# PWMSS_EPWM register map
Vendor: Texas Instruments
Peripheral module from a debugger description file (folder am437x).
Registers are 16-bit, access per field, no defined reset value unless marked. A register's access mark holds for its fields unless they carry their own. Offsets are as the file gives them; lines under a group give offsets from that group; [hi:lo] are bit positions; {n}, {i} and the like mark numbered series; 'fields as' and 'values as' point back to an identical list; <NAME> marks a mode.

## PWMSS_EPWM
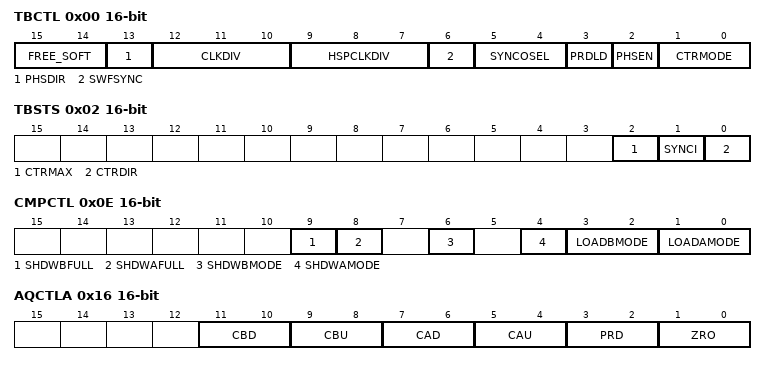
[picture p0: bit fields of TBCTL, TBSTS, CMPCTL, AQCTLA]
0x00 TBCTL rw
  [15:14] FREE_SOFT — Emulation Mode Bits. These bits select the behavior of the ePWM time-base counter during emulation suspend events. Emulation debug events can be set up in the Debug Subsystem.
    3=en_4_0x3 (Free run); 2=en_3_0x2 (Free run); 1=en_2_0x1 (Stop when counter completes a whole cycle. (a) Up-count mode - stop when the time-base counter = period (TBCNT = TBPRD). (b) Down-count mode - stop when the time-base counter = 0000 (TBCNT = 0000h). (c) Up-down-count mode - stop when the time-base counter = 0000 (TBCNT = 0000h).); 0=en_1_0x0 (Stop after the next time-base counter increment or decrement)
  [13] PHSDIR — Phase Direction Bit. This bit is only used when the time-base counter is configured in the up-down-count mode. The PHSDIR bit indicates the direction the time-base counter (TBCNT) will count after a synchronization event occurs and a new phase value is loaded from the phase (TBPHS) register. This is irrespective of the direction of the counter before the synchronization event.. In the up-count and down-count modes this bit is ignored.
    1=en_2_0x1 (Count up after the synchronization event.); 0=en_1_0x0 (Count down after the synchronization event.)
  [12:10] CLKDIV — Time-base Clock Prescale Bits. These bits determine part of the time-base clock prescale value. TBCLK = SYSCLKOUT/(HSPCLKDIV * CLKDIV)
    7=en_8_0x7 (/128); 6=en_7_0x6 (/64); 5=en_6_0x5 (/32); 4=en_5_0x4 (/16); 3=en_4_0x3 (/8); 2=en_3_0x2 (/4); 1=en_2_0x1 (/2); 0=en_1_0x0 (/1 (default on reset))
  [9:7] HSPCLKDIV — High-Speed Time-base Clock Prescale Bits. These bits determine part of the time-base clock prescale value. TBCLK = SYSCLKOUT/(HSPCLKDIV * CLKDIV). This divisor emulates the HSPCLK in the TMS320x281x system as used on the Event Manager (EV) peripheral.
    7=en_8_0x7 (/14); 6=en_7_0x6 (/12); 5=en_6_0x5 (/10); 4=en_5_0x4 (/8); 3=en_4_0x3 (/6); 2=en_3_0x2 (/4); 1=en_2_0x1 (/2 (default on reset)); 0=en_1_0x0 (/1)
  [6] SWFSYNC — Software Forced Synchronization Pulse.
    1=en_2_0x1 (Writing a 1 forces a one-time synchronization pulse to be generated. This event is ORed with the EPWMxSYNCI input of the ePWM module. SWFSYNC is valid (operates) only when EPWMxSYNCI is selected by SYNCOSEL = 00.); 0=en_1_0x0 (Writing a 0 has no effect and reads always return a 0.)
  [5:4] SYNCOSEL — Synchronization Output Select. These bits select the source of the EPWMxSYNCO signal.
    3=en_4_0x3 (Disable EPWMxSYNCO signal); 2=en_3_0x2 (CTR = CMPB - Time-base counter equal to counter-compare B (TBCNT = CMPB)); 1=en_2_0x1 (CTR = 0 - Time-base counter equal to zero (TBCNT = 0000h)); 0=en_1_0x0 (EPWMxSYNC:)
  [3] PRDLD — Active Period Register Load From Shadow Register Select
    1=en_2_0x1 (Load the TBPRD register immediately without using a shadow register. A write or read to the TBPRD register directly accesses the active register.); 0=en_1_0x0 (The period register (TBPRD) is loaded from its shadow register when the time-base counter, TBCNT, is equal to zero. A write or read to the TBPRD register accesses the shadow register.)
  [2] PHSEN — Counter Register Load From Phase Register Enable
    1=en_2_0x1 (Load the time-base counter with the phase register when an EPWMxSYNCI input signal occurs or when a software synchronization is forced by the SWFSYNC bit.); 0=en_1_0x0 (Do not load the time-base counter (TBCNT) from the time-base phase register (TBPHS))
  [1:0] CTRMODE — Counter Mode. The time-base counter mode is normally configured once and not changed during normal operation. If you change the mode of the counter, the change will take effect at the next TBCLK edge and the current counter value shall increment or decrement from the value before the mode change. These bits set the time-base counter mode of operation as follows:
    3=en_4_0x3 (Stop-freeze counter operation (default on reset)); 2=en_3_0x2 (Up-down-count mode); 1=en_2_0x1 (Down-count mode); 0=en_1_0x0 (Up-count mode)
0x02 TBSTS access not given
  [2] CTRMAX — Time-Base Counter Max Latched Status Bit.
    1=en_2_0x1 (Reading a 1 on this bit indicates that the time-base counter reached the max value 0xFFFF. Writing a 1 to this bit will clear the latched event.); 0=en_1_0x0 (Reading a 0 indicates the time-base counter never reached its maximum value. Writing a 0 will have no effect.)
  [1] SYNCI wo — Input Synchronization Latched Status Bit.
    1=en_2_0x1 (Reading a 1 on this bit indicates that an external synchronization event has occurred (EPWMxSYNCI). Writing a 1 to this bit will clear the latched event.); 0=en_1_0x0 (Writing a 0 will have no effect. Reading a 0 indicates no external synchronization event has occurred.)
  [0] CTRDIR ro — Time-Base Counter Direction Status Bit. At reset, the counter is frozen, therefore, this bit has no meaning. To make this bit meaningful, you must first set the appropriate mode via TBCTL[CTRMODE].
    1=en_2_0x1 (Time-Base Counter is currently counting up.); 0=en_1_0x0 (Time-Base Counter is currently counting down.)
0x04 TBPHSHR
  [15:8] TBPHSH rw — Time-base phase high-resolution bits
0x06 TBPHS rw — This register is only available on ePWM instances that include the high-resolution PWM (HRPWM) extension, otherwise, this location is reserved.
  [15:0] TBPHS — These bits set time-base counter phase of the selected ePWM relative to the time-base that is supplying the synchronization input signal. (a) If TBCTL[PHSEN] = 0, then the synchronization event is ignored and the time-base counter is not loaded with the phase. (b) If TBCTL[PHSEN] = 1, then the time-base counter (TBCNT) will be loaded with the phase (TBPHS) when a synchronization event occurs. The synchronization event can be initiated by the input synchronization signal (EPWMxSYNCI) or by a software forced synchronization.
0x08 TBCNT rw
  [15:0] TBCNT — Reading these bits gives the current time-base counter value. Writing to these bits sets the current time-base counter value. The update happens as soon as the write occurs. The write is NOT synchronized to the time-base clock (TBCLK) and the register is not shadowed.
0x0A TBPRD rw
  [15:0] TBPRD — These bits determine the period of the time-base counter. This sets the PWM frequency. Shadowing of this register is enabled and disabled by the TBCTL[PRDLD] bit. By default this register is shadowed. (a) If TBCTL[PRDLD] = 0, then the shadow is enabled and any write or read will automatically go to the shadow register. In this case, the active register will be loaded from the shadow register when the time-base counter equals zero. (b) If TBCTL[PRDLD] = 1, then the shadow is disabled and any write or read will go directly to the active register, that is the register actively controlling the hardware. (c) The active and shadow registers share the same memory map address.
0x0E CMPCTL
  [9] SHDWBFULL ro — Counter-compare B (CMPB) Shadow Register Full Status Flag. This bit self clears once a load-strobe occurs.
    1=en_2_0x1 (Indicates the CMPB shadow FIFO is full. A CPU write will overwrite current shadow value.); 0=en_1_0x0 (CMPB shadow FIFO not full yet)
  [8] SHDWAFULL ro — Counter-compare A (CMPA) Shadow Register Full Status Flag. The flag bit is set when a 32 bit write to CMPA:CMPAHR register or a 16 bit write to CMPA register is made. A 16 bit write to CMPAHR register will not affect the flag. This bit self clears once a load-strobe occurs.
    1=en_2_0x1 (Indicates the CMPA shadow FIFO is full, a CPU write will overwrite the current shadow value.); 0=en_1_0x0 (CMPA shadow FIFO not full yet)
  [6] SHDWBMODE rw — Counter-compare B (CMPB) Register Operating Mode.
    1=en_2_0x1 (Immediate mode. Only the active compare B register is used. All writes and reads directly access the active register for immediate compare action.); 0=en_1_0x0 (Shadow mode. Operates as a double buffer. All writes via the CPU access the shadow register.)
  [4] SHDWAMODE rw — Counter-compare A (CMPA) Register Operating Mode.
    1=en_2_0x1 (Immediate mode. Only the active compare register is used. All writes and reads directly access the active register for immediate compare action); 0=en_1_0x0 (Shadow mode. Operates as a double buffer. All writes via the CPU access the shadow register.)
  [3:2] LOADBMODE rw — Active Counter-Compare B (CMPB) Load From Shadow Select Mode. This bit has no effect in immediate mode (CMPCTL[SHDWBMODE] = 1).
    3=en_4_0x3 (Freeze (no loads possible)); 2=en_3_0x2 (Load on either CTR = 0 or CTR = PRD); 1=en_2_0x1 (Load on CTR = PRD - Time-base counter equal to period (TBCNT = TBPRD)); 0=en_1_0x0 (Load on CTR = 0 - Time-base counter equal to zero (TBCNT = 0000h))
  [1:0] LOADAMODE rw — Active Counter-Compare A (CMPA) Load From Shadow Select Mode. This bit has no effect in immediate mode (CMPCTL[SHDWAMODE] = 1).
    values as LOADBMODE
0x10 CMPAHR — This register is only available on ePWM instances that include the high-resolution PWM (HRPWM) extension; otherwise, this location is reserved.
  [15:8] CMPAHR rw — Compare A High-Resolution register bits for MEP step control. A minimum value of 1h is needed to enable HRPWM capabilities. Valid MEP range of operation 1-255h.
0x12 CMPA rw
  [15:0] CMPA — The value in the active CMPA register is continuously compared to the time-base counter (TBCNT). When the values are equal, the counter-compare module generates a "time-base counter equal to counter compare A" event. This event is sent to the action-qualifier where it is qualified and converted it into one or more actions. These actions can be applied to either the EPWMxA or the EPWMxB output depending on the configuration of the AQCTLA and AQCTLB registers. The actions that can be defined in the AQCTLA and AQCTLB registers include the following. (a) Do nothing the event is ignored. (b) Clear - Pull the EPWMxA and/or EPWMxB signal low. (c) Set - Pull the EPWMxA and/or EPWMxB signal high. (d) Toggle the EPWMxA and/or EPWMxB signal. Shadowing of this register is enabled and disabled by the CMPCTL[SHDWAMODE] bit. By default this register is shadowed. (a) If CMPCTL[SHDWAMODE] = 0, then the shadow is enabled and any write or read will automatically go to the shadow register. In this case, the CMPCTL[LOADAMODE] bit field determines which event will load the active register from the shadow register. (b) Before a write, the CMPCTL[SHDWAFULL] bit can be read to determine if the shadow register is currently full. (c) If CMPCTL[SHDWAMODE] = 1, then the shadow register is disabled and any write or read will go directly to the active register, that is the register actively controlling the hardware. (d) In either mode, the active and shadow registers share the same memory map address.
0x14 CMPB rw
  [15:0] CMPB — The value in the active CMPB register is continuously compared to the time-base counter (TBCNT). When the values are equal, the counter-compare module generates a "time-base counter equal to counter compare B" event. This event is sent to the action-qualifier where it is qualified and converted it into one or more actions. These actions can be applied to either the EPWMxA or the EPWMxB output depending on the configuration of the AQCTLA and AQCTLB registers. The actions that can be defined in the AQCTLA and AQCTLB registers include the following. (a) Do nothing, the event is ignored. (b) Clear - Pull the EPWMxA and/or EPWMxB signal low. (c) Set - Pull the EPWMxA and/or EPWMxB signal high. (d) Toggle the EPWMxA and/or EPWMxB signal. Shadowing of this register is enabled and disabled by the CMPCTL[SHDWBMODE] bit. By default this register is shadowed. (a) If CMPCTL[SHDWBMODE] = 0, then the shadow is enabled and any write or read will automatically go to the shadow register. In this case, the CMPCTL[LOADBMODE] bit field determines which event will load the active register from the shadow register: (b) Before a write, the CMPCTL[SHDWBFULL] bit can be read to determine if the shadow register is currently full. (c) If CMPCTL[SHDWBMODE] = 1, then the shadow register is disabled and any write or read will go directly to the active register, that is the register actively controlling the hardware. (d) In either mode, the active and shadow registers share the same memory map address.
0x16 AQCTLA
  [all] fields
    3=en_4_0x3 (Toggle EPWMxA output - low output signal will be forced high, and a high signal will be forced low.); 2=en_3_0x2 (Set - force EPWMxA output high.); 1=en_2_0x1 (Clear - force EPWMxA output low.); 0=en_1_0x0 (Do nothing (action disabled))
  [11:10] CBD rw — Action when the time-base counter equals the active CMPB register and the counter is decrementing.
  [9:8] CBU rw — Action when the counter equals the active CMPB register and the counter is incrementing.
  [7:6] CAD rw — Action when the counter equals the active CMPA register and the counter is decrementing.
  [5:4] CAU rw — Action when the counter equals the active CMPA register and the counter is incrementing.
  [3:2] PRD rw — Action when the counter equals the period. Note: By definition, in count up-down mode when the counter equals period the direction is defined as 0 or counting down.
  [1:0] ZRO rw — Action when counter equals zero. Note: By definition, in count up-down mode when the counter equals 0 the direction is defined as 1 or counting up.
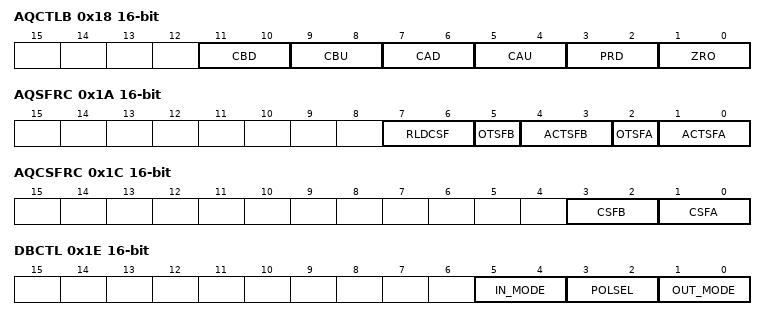
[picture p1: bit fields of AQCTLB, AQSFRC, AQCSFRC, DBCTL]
0x18 AQCTLB
  [all] fields
    3=en_4_0x3 (Toggle EPWMxB output - low output signal will be forced high, and a high signal will be forced low.); 2=en_3_0x2 (Set - force EPWMxB output high.); 1=en_2_0x1 (Clear - force EPWMxB output low.); 0=en_1_0x0 (Do nothing (action disabled))
  [11:10] CBD rw — Action when the counter equals the active CMPB register and the counter is decrementing.
  [9:8] CBU rw — Action when the counter equals the active CMPB register and the counter is incrementing.
  [7:6] CAD rw — Action when the counter equals the active CMPA register and the counter is decrementing.
  [5:4] CAU rw — Action when the counter equals the active CMPA register and the counter is incrementing.
  [3:2] PRD rw — Action when the counter equals the period. Note: By definition, in count up-down mode when the counter equals period the direction is defined as 0 or counting down.
  [1:0] ZRO rw — Action when counter equals zero. Note: By definition, in count up-down mode when the counter equals 0 the direction is defined as 1 or counting up.
0x1A AQSFRC
  [7:6] RLDCSF rw — AQCSFRC Active Register Reload From Shadow Options.
    3=en_4_0x3 (Load immediately (the active register is directly accessed by the CPU and is not loaded from the shadow register).); 2=en_3_0x2 (Load on event counter equals zero or counter equals period); 1=en_2_0x1 (Load on event counter equals period); 0=en_1_0x0 (Load on event counter equals zero)
  [5] OTSFB rw — One-Time Software Forced Event on Output B.
    1=en_2_0x1 (Initiates a single s/w forced event); 0=en_1_0x0 (Writing a 0 (zero) has no effect. Always reads back a 0. This bit is auto cleared once a write to this register is complete, that is, a forced event is initiated. This is a one-shot forced event. It can be overridden by another subsequent event on output B.)
  [4:3] ACTSFB rw — Action when One-Time Software Force B Is invoked
    3=en_4_0x3 (Toggle (Low -> High, High -> Low). Note: This action is not qualified by counter direction (CNT_dir)); 2=en_3_0x2 (Set (high)); 1=en_2_0x1 (Clear (low)); 0=en_1_0x0 (Does nothing (action disabled))
  [2] OTSFA rw — One-Time Software Forced Event on Output A.
    1=en_2_0x1 (Initiates a single software forced event.); 0=en_1_0x0 (Writing a 0 (zero) has no effect. Always reads back a 0. This bit is auto cleared once a write to this register is complete (that is, a forced event is initiated).)
  [1:0] ACTSFA rw — Action When One-Time Software Force A Is Invoked.
    3=en_4_0x3 (Toggle (Low -> High, High -> Low). Note: This action is not qualified by counter direction (CNT_dir)); 2=en_3_0x2 (Set (high).); 1=en_2_0x1 (Clear (low).); 0=en_1_0x0 (Does nothing (action disabled).)
0x1C AQCSFRC
  [3:2] CSFB rw — Continuous Software Force on Output B. In immediate mode, a continuous force takes effect on the next TBCLK edge. In shadow mode, a continuous force takes effect on the next TBCLK edge after a shadow load into the active register. To configure shadow mode, use AQSFRC[RLDCSF].
    3=en_4_0x3 (Software forcing is disabled and has no effect); 2=en_3_0x2 (Forces a continuous high on output B); 1=en_2_0x1 (Forces a continuous low on output B); 0=en_1_0x0 (Forcing disabled, that is, has no effect)
  [1:0] CSFA rw — Continuous Software Force on Output A In immediate mode, a continuous force takes effect on the next TBCLK edge. In shadow mode, a continuous force takes effect on the next TBCLK edge after a shadow load into the active register.
    3=en_4_0x3 (Software forcing is disabled and has no effect); 2=en_3_0x2 (Forces a continuous high on output A); 1=en_2_0x1 (Forces a continuous low on output A); 0=en_1_0x0 (Forcing disabled, that is, has no effect)
0x1E DBCTL
  [5:4] IN_MODE rw — Dead Band Input Mode Control. Bit 5 controls the S5 switch and bit 4 controls the S4 switch. This allows you to select the input source to the falling-edge and rising-edge delay. To produce classical dead-band waveforms, the default is EPWMxA In is the source for both falling and rising-edge delays.
    3=en_4_0x3 (EPWMxB In (from the action-qualifier) is the source for both rising-edge delay and falling-edge delayed signal.); 2=en_3_0x2 (EPWMxA In (from the action-qualifier) is the source for rising-edge delayed signal. EPWMxB In (from the action-qualifier) is the source for falling-edge delayed signal.); 1=en_2_0x1 (EPWMxB In (from the action-qualifier) is the source for rising-edge delayed signal. EPWMxA In (from the action-qualifier) is the source for falling-edge delayed signal.); 0=en_1_0x0 (EPWMxA In (from the action-qualifier) is the source for both falling-edge and rising-edge delay.)
  [3:2] POLSEL rw — Polarity Select Control. Bit 3 controls the S3 switch and bit 2 controls the S2 switch. This allows you to selectively invert one of the delayed signals before it is sent out of the dead-band submodule. The following descriptions correspond to classical upper/lower switch control as found in one leg of a digital motor control inverter. These assume that DBCTL[OUT_MODE] = 1,1 and DBCTL[IN_MODE] = 0,0. Other enhanced modes are also possible, but not regarded as typical usage modes.
    3=en_4_0x3 (Active low (AL) mode. Both EPWMxA and EPWMxB are inverted.); 2=en_3_0x2 (Active high complementary (AHC). EPWMxB is inverted.); 1=en_2_0x1 (Active low complementary (ALC) mode. EPWMxA is inverted.); 0=en_1_0x0 (Active high (AH) mode. Neither EPWMxA nor EPWMxB is inverted (default).)
  [1:0] OUT_MODE rw — Dead-band Output Mode Control. Bit 1 controls the S1 switch and bit 0 controls the S0 switch. This allows you to selectively enable or bypass the dead-band generation for the falling-edge and rising-edge delay.
    3=en_4_0x3 (Dead-band is fully enabled for both rising-edge delay on output EPWMxA and falling-edge delay on output EPWMxB. The input signal for the delay is determined by DBCTL[IN_MODE].); 2=en_3_0x2 (Disable falling-edge delay. The EPWMxB signal from the action-qualifier is passed straight through to the EPWMxB input of the PWM-chopper submodule. The rising-edge delayed signal is seen on output EPWMxA. The input signal for the delay is determined by DBCTL[IN_MODE].); 1=en_2_0x1 (Disable rising-edge delay. The EPWMxA signal from the action-qualifier is passed straight through to the EPWMxA input of the PWM-chopper submodule. The falling-edge delayed signal is seen on output EPWMxB. The input signal for the delay is determined by DBCTL[IN_MODE].); 0=en_1_0x0 (Dead-band generation is bypassed for both output signals. In this mode, both the EPWMxA and EPWMxB output signals from the action-qualifier are passed directly to the PWM-chopper submodule. In this mode, the POLSEL and IN_MODE bits have no effect.)
0x20 DBRED
  [9:0] DEL rw — Rising Edge Delay Count. 10 bit counter.
0x22 DBFED
  [9:0] DEL rw — Falling Edge Delay Count. 10 bit counter
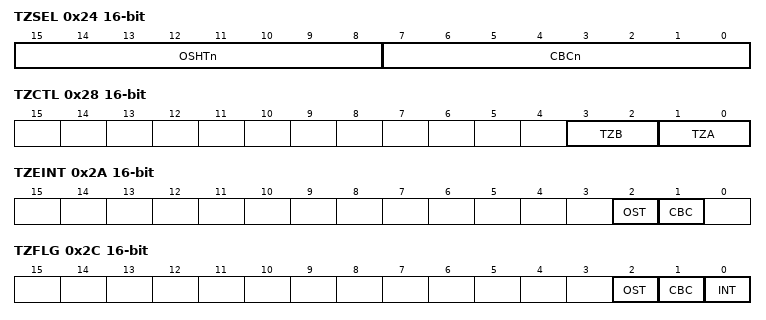
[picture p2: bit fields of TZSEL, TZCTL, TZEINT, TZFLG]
0x24 TZSEL rw
  [15:8] OSHTn — Trip-zone n (TZn) select. One-Shot (OSHT) trip-zone enable/disable. When any of the enabled pins go low, a one-shot trip event occurs for this ePWM module. When the event occurs, the action defined in the TZCTL register is taken on the EPWMxA and EPWMxB outputs. The one-shot trip condition remains latched until you clear the condition via the TZCLR register.
    1=en_2_0x1 (Enable TZn as a one-shot trip source for this ePWM module.); 0=en_1_0x0 (Disable TZn as a one-shot trip source for this ePWM module.)
  [7:0] CBCn — Trip-zone n (TZn) select. Cycle-by-Cycle (CBC) trip-zone enable/disable. When any of the enabled pins go low, a cycle-by-cycle trip event occurs for this ePWM module. When the event occurs, the action defined in the TZCTL register is taken on the EPWMxA and EPWMxB outputs. A cycle-by-cycle trip condition is automatically cleared when the time-base counter reaches zero.
    1=en_2_0x1 (Enable TZn as a CBC trip source for this ePWM module.); 0=en_1_0x0 (Disable TZn as a CBC trip source for this ePWM module.)
0x28 TZCTL
  [3:2] TZB rw — When a trip event occurs the following action is taken on output EPWMxB. Which trip-zone pins can cause an event is defined in the TZSEL register.
    3=en_4_0x3 (Do nothing, no action is taken on EPWMxB.); 2=en_3_0x2 (Force EPWMxB to a low state); 1=en_2_0x1 (Force EPWMxB to a high state); 0=en_1_0x0 (High impedance (EPWMxB = High-impedance state))
  [1:0] TZA rw — When a trip event occurs the following action is taken on output EPWMxA. Which trip-zone pins can cause an event is defined in the TZSEL register.
    3=en_4_0x3 (Do nothing, no action is taken on EPWMxA.); 2=en_3_0x2 (Force EPWMxA to a low state); 1=en_2_0x1 (Force EPWMxA to a high state); 0=en_1_0x0 (High impedance (EPWMxA = High-impedance state))
0x2A TZEINT
  [2] OST rw — Trip-zone One-Shot Interrupt Enable
    1=en_2_0x1 (Enable Interrupt generation; a one-shot trip event will cause a EPWMxTZINT interrupt.); 0=en_1_0x0 (Disable one-shot interrupt generation)
  [1] CBC rw — Trip-zone Cycle-by-Cycle Interrupt Enable
    1=en_2_0x1 (Enable interrupt generation; a cycle-by-cycle trip event will cause an EPWMxTZINT interrupt.); 0=en_1_0x0 (Disable cycle-by-cycle interrupt generation.)
0x2C TZFLG ro
  [2] OST — Latched Status Flag for A One-Shot Trip Event.
    1=en_2_0x1 (Indicates a trip event has occurred on a pin selected as a one-shot trip source. This bit is cleared by writing the appropriate value to the TZCLR register.); 0=en_1_0x0 (No one-shot trip event has occurred.)
  [1] CBC — Latched Status Flag for Cycle-By-Cycle Trip Event
    1=en_2_0x1 (Indicates a trip event has occurred on a pin selected as a cycle-by-cycle trip source. The TZFLG[CBC] bit will remain set until it is manually cleared by the user. If the cycle-by-cycle trip event is still present when the CBC bit is cleared, then CBC will be immediately set again. The specified condition on the pins is automatically cleared when the ePWM time-base counter reaches zero (TBCNT = 0000h) if the trip condition is no longer present. The condition on the pins is only cleared when the TBCNT = 0000h no matter where in the cycle the CBC flag is cleared. This bit is cleared by writing the appropriate value to the TZCLR register.); 0=en_1_0x0 (No cycle-by-cycle trip event has occurred.)
  [0] INT — Latched Trip Interrupt Status Flag
    1=en_2_0x1 (Indicates an EPWMxTZINT interrupt was generated because of a trip condition. No further EPWMxTZINT interrupts will be generated until this flag is cleared. If the interrupt flag is cleared when either CBC or OST is set, then another interrupt pulse will be generated. Clearing all flag bits will prevent further interrupts. This bit is cleared by writing the appropriate value to the TZCLR register.); 0=en_1_0x0 (Indicates no interrupt has been generated.)
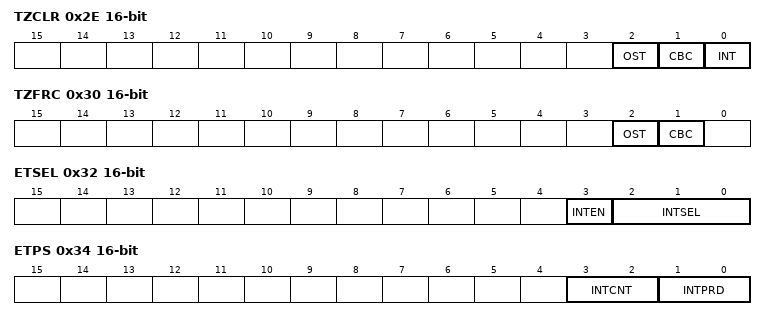
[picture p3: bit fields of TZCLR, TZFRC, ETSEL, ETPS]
0x2E TZCLR
  [2] OST rw — Clear Flag for One-Shot Trip (OST) Latch
    1=en_2_0x1 (Clears this Trip (set) condition.); 0=en_1_0x0 (Has no effect. Always reads back a 0.)
  [1] CBC rw — Clear Flag for Cycle-By-Cycle (CBC) Trip Latch
    values as OST
  [0] INT rw — Global Interrupt Clear Flag
    1=en_2_0x1 (Clears the trip-interrupt flag for this ePWM module (TZFLG[INT]). Note: No further EPWMxTZINT interrupts will be generated until the flag is cleared. If the TZFLG[INT] bit is cleared and any of the other flag bits are set, then another interrupt pulse will be generated. Clearing all flag bits will prevent further interrupts.); 0=en_1_0x0 (Has no effect. Always reads back a 0.)
0x30 TZFRC
  [2] OST rw — Force a One-Shot Trip Event via Software
    1=en_2_0x1 (Forces a one-shot trip event and sets the TZFLG[OST] bit.); 0=en_1_0x0 (Writing of 0 is ignored. Always reads back a 0.)
  [1] CBC rw — Force a Cycle-by-Cycle Trip Event via Software
    1=en_2_0x1 (Forces a cycle-by-cycle trip event and sets the TZFLG[CBC] bit.); 0=en_1_0x0 (Writing of 0 is ignored. Always reads back a 0.)
0x32 ETSEL
  [3] INTEN rw — Enable ePWM Interrupt (EPWMx_INT) Generation
    1=en_2_0x1 (Enable EPWMx_INT generation); 0=en_1_0x0 (Disable EPWMx_INT generation)
  [2:0] INTSEL rw — ePWM Interrupt (EPWMx_INT) Selection Options
    7=en_8_0x7 (Enable event - time-base counter equal to CMPB when the timer is decrementing.); 6=en_7_0x6 (Enable event - time-base counter equal to CMPB when the timer is incrementing.); 5=en_6_0x5 (Enable event time-base counter equal to CMPA when the timer is decrementing.); 4=en_5_0x4 (Enable event time-base counter equal to CMPA when the timer is incrementing.); 3=en_4_0x3 (Reserved); 2=en_3_0x2 (Enable event time-base counter equal to period (TBCNT = TBPRD)); 1=en_2_0x1 (Enable event time-base counter equal to zero. (TBCNT = 0000h)); 0=en_1_0x0 (Reserved)
0x34 ETPS
  [3:2] INTCNT ro — ePWM Interrupt Event (EPWMx_INT) Counter Register. These bits indicate how many selected ETSEL[INTSEL] events have occurred. These bits are automatically cleared when an interrupt pulse is generated. If interrupts are disabled, ETSEL[INT] = 0 or the interrupt flag is set, ETFLG[INT] = 1, the counter will stop counting events when it reaches the period value ETPS[INTCNT] = ETPS[INTPRD].
    3=en_4_0x3 (3 events have occurred.); 2=en_3_0x2 (2 events have occurred.); 1=en_2_0x1 (1 event has occurred.); 0=en_1_0x0 (No events have occurred.)
  [1:0] INTPRD rw — ePWM Interrupt (EPWMx_INT) Period Select. These bits determine how many selected ETSEL[INTSEL] events need to occur before an interrupt is generated. To be generated, the interrupt must be enabled (ETSEL[INT] = 1). If the interrupt status flag is set from a previous interrupt (ETFLG[INT] = 1) then no interrupt will be generated until the flag is cleared via the ETCLR[INT] bit. This allows for one interrupt to be pending while another is still being serviced. Once the interrupt is generated, the ETPS[INTCNT] bits will automatically be cleared. Writing a INTPRD value that is the same as the current counter value will trigger an interrupt if it is enabled and the status flag is clear. Writing a INTPRD value that is less than the current counter value will result in an undefined state. If a counter event occurs at the same instant as a new zero or non-zero INTPRD value is written, the counter is incremented.
    3=en_4_0x3 (Generate interrupt on ETPS[INTCNT] = 1,1 (third event)); 2=en_3_0x2 (Generate interrupt on ETPS[INTCNT] = 1,0 (second event)); 1=en_2_0x1 (Generate an interrupt on the first event INTCNT = 01 (first event)); 0=en_1_0x0 (Disable the interrupt event counter. No interrupt will be generated and ETFRC[INT] is ignored.)
0x36 ETFLG ro
  [0] INT — Latched ePWM Interrupt (EPWMx_INT) Status Flag
    1=en_2_0x1 (Indicates that an ePWMx interrupt (EWPMx_INT) was generated. No further interrupts will be generated until the flag bit is cleared. Up to one interrupt can be pending while the ETFLG[INT] bit is still set. If an interrupt is pending, it will not be generated until after the ETFLG[INT] bit is cleared.); 0=en_1_0x0 (Indicates no event occurred)
0x38 ETCLR ro
  [0] INT — ePWM Interrupt (EPWMx_INT) Flag Clear Bit
    1=en_2_0x1 (Clears the ETFLG[INT] flag bit and enable further interrupts pulses to be generated. NOTE: Interrupts can also used as DMA events, and this will also enable further DMA events to be generated); 0=en_1_0x0 (Writing a 0 has no effect. Always reads back a 0.)
0x3A ETFRC ro
  [0] INT — INT Force Bit. The interrupt will only be generated if the event is enabled in the ETSEL register. The INT flag bit will be set regardless.
    1=en_2_0x1 (Generates an interrupt on EPWMxINT and set the INT flag bit. This bit is used for test purposes.); 0=en_1_0x0 (Writing 0 to this bit will be ignored. Always reads back a 0.)
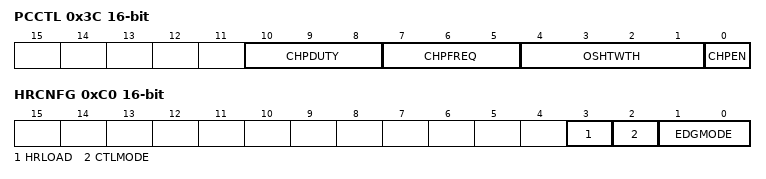
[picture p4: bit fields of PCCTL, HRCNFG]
0x3C PCCTL
  [10:8] CHPDUTY rw — Chopping Clock Duty Cycle
    7=en_8_0x7 (Reserved.); 6=en_7_0x6 (Duty = 7/8 (87.5%)); 5=en_6_0x5 (Duty = 6/8 (75.0%)); 4=en_5_0x4 (Duty = 5/8 (62.5%)); 3=en_4_0x3 (Duty = 4/8 (50.0%)); 2=en_3_0x2 (Duty = 3/8 (37.5%)); 1=en_2_0x1 (Duty = 2/8 (25.0%)); 0=en_1_0x0 (Duty = 1/8 (12.5%))
  [7:5] CHPFREQ rw — Chopping Clock Frequency
    {v}=en_{v+1}_{0x0+v} (Divide by {v+1}.) (v=1..7); 0=en_1_0x0 (Divide by 1 (no prescale).)
  [4:1] OSHTWTH rw — One-Shot Pulse Width
    15=en_5_0xF (16 - SYSCLKOUT/8 wide); {v}=en_{v+1}_{0x0+v} ({v+1} - SYSCLKOUT/8 wide) (v=0..3)
  [0] CHPEN rw — PWM-chopping Enable
    1=en_2_0x1 (Enable chopping function); 0=en_1_0x0 (Disable (bypass) PWM chopping function)
0xC0 HRCNFG — This register is only available on ePWM instances that include the high-resolution PWM (HRPWM) extension; otherwise, this location is reserved.
  [3] HRLOAD rw — Shadow mode bit - Selects the time event that loads the CMPAHR shadow value into the active register. Note: Load mode selection is valid only if CTLMODE = 0 has been selected. You should select this event to match the selection of the CMPA load mode (CMPCTL[LOADMODE] bits) in the EPWM module as follows: 0x 0: Load on CTR = 0 Time-base counter equal to zero (TBCNT = 0000h) 0x 1: Load on CTR = PRD Time-base counter equal to period (TBCNT = TBPRD) 0x 2: Load on either CTR = 0 or CTR = PRD (should not be used with HRPWM) 0x 3: Freeze (no loads possible should not be used with HRPWM)
    1=en_2_0x1 (CTR = PRD (counter equal period)); 0=en_1_0x0 (CTR = 0 (counter equals zero))
  [2] CTLMODE rw — Control Mode Bits - Selects the register (CMP or TBPHS) that controls the MEP.
    1=en_2_0x1 (TBPHSHR(8) Register controls the edge position (this is phase control mode).); 0=en_1_0x0 (CMPAHR(8) Register controls the edge position (this is duty control mode). (default on reset))
  [1:0] EDGMODE rw — Edge Mode Bits - Selects the edge of the PWM that is controlled by the micro-edge position (MEP) logic.
    3=en_4_0x3 (MEP control of both edges); 2=en_3_0x2 (MEP control of falling edge); 1=en_2_0x1 (MEP control of rising edge); 0=en_1_0x0 (HRPWM capability is disabled (default on reset))
